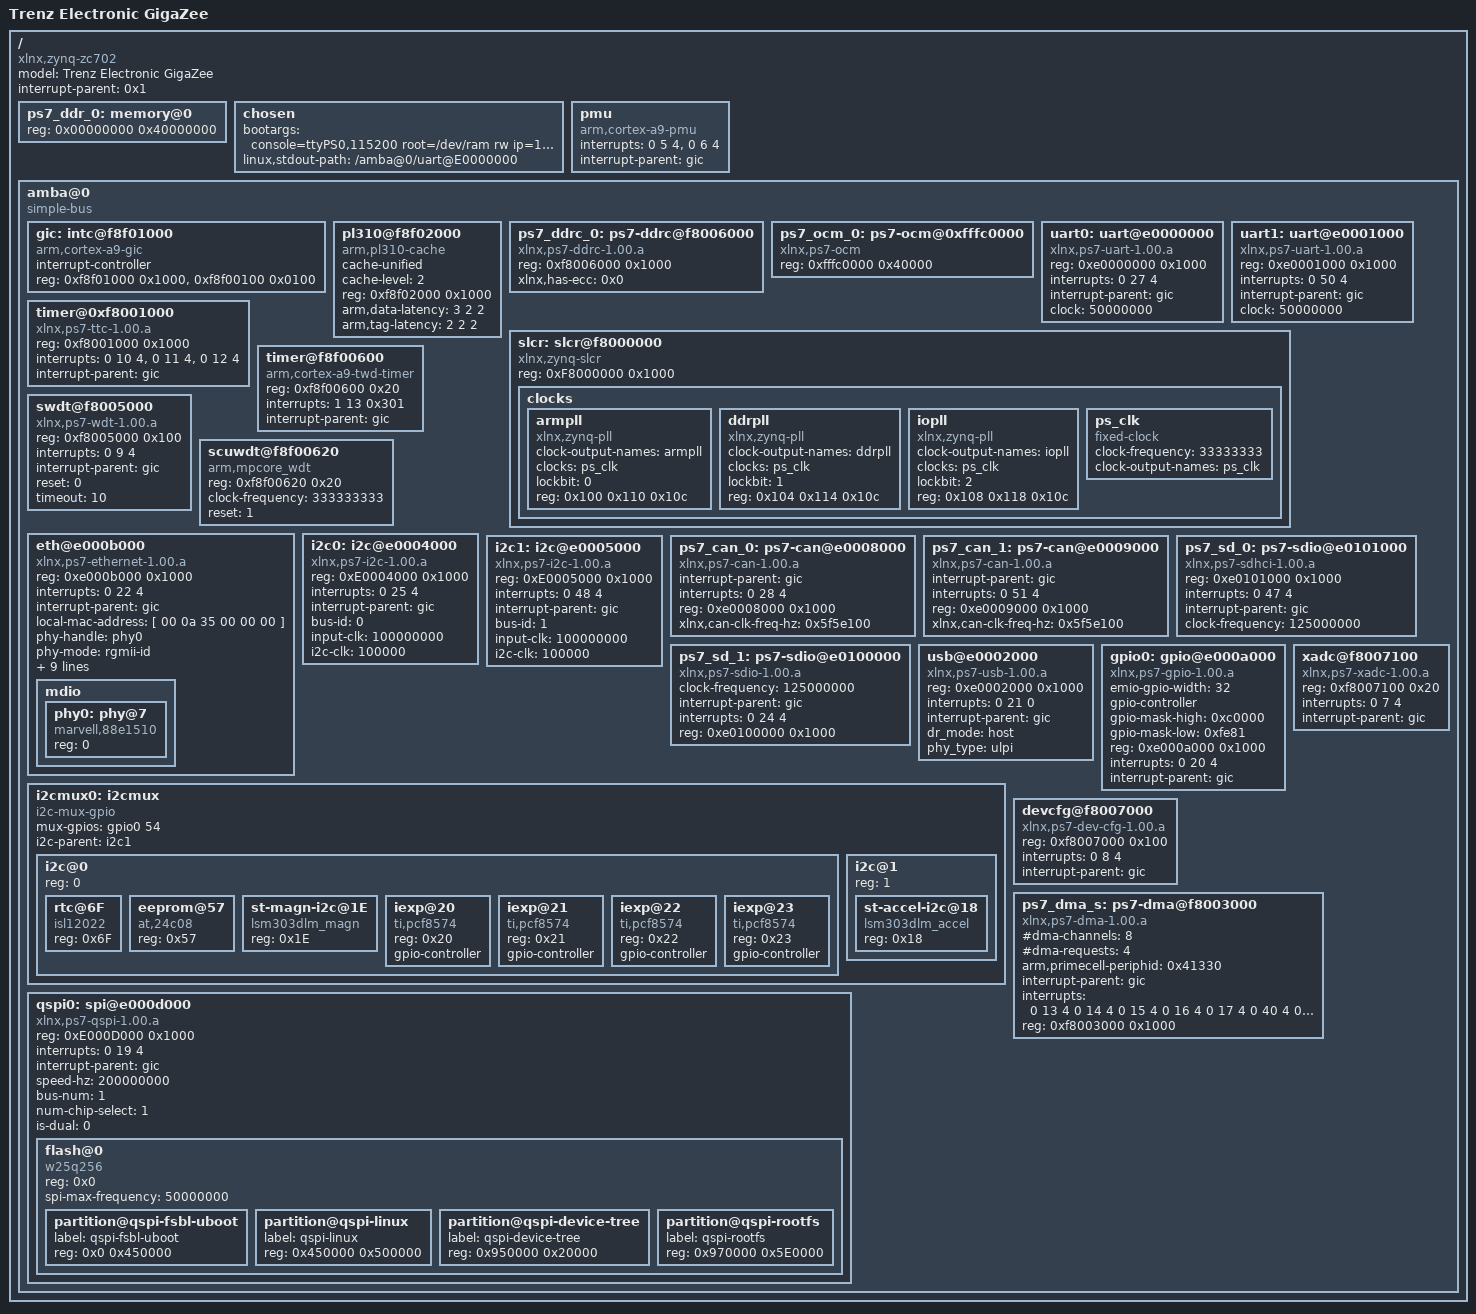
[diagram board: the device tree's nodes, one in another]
/*
-- Copyright (C) 2013 Trenz Electronic GmbH
--
-- Permission is hereby granted, free of charge, to any person obtaining a 
-- copy of this software and associated documentation files (the "Software"), 
-- to deal in the Software without restriction, including without limitation 
-- the rights to use, copy, modify, merge, publish, distribute, sublicense, 
-- and/or sell copies of the Software, and to permit persons to whom the 
-- Software is furnished to do so, subject to the following conditions:
-- 
-- The above copyright notice and this permission notice shall be included 
-- in all copies or substantial portions of the Software.
--
-- THE SOFTWARE IS PROVIDED "AS IS", WITHOUT WARRANTY OF ANY KIND, EXPRESS 
-- OR IMPLIED, INCLUDING BUT NOT LIMITED TO THE WARRANTIES OF MERCHANTABILITY, 
-- FITNESS FOR A PARTICULAR PURPOSE AND NONINFRINGEMENT. IN NO EVENT SHALL THE 
-- AUTHORS OR COPYRIGHT HOLDERS BE LIABLE FOR ANY CLAIM, DAMAGES OR OTHER 
-- LIABILITY, WHETHER IN AN ACTION OF CONTRACT, TORT OR OTHERWISE, ARISING 
-- FROM, OUT OF OR IN CONNECTION WITH THE SOFTWARE OR THE USE OR OTHER DEALINGS 
-- IN THE SOFTWARE.
 */
/dts-v1/;

/ {
	model = "Trenz Electronic GigaZee";
	compatible = "xlnx,zynq-zc702";
	#address-cells = <0x1>;
	#size-cells = <0x1>;
	interrupt-parent = <0x1>;

	ps7_ddr_0: memory@0 {
		device_type = "memory";
		reg = <0x00000000 0x40000000>;
	};

	chosen {
		/*bootargs = "console=ttyPS0,115200 root=/dev/ram rw ip=:::::eth0:dhcp earlyprintk";*/					/*rootfs in memory, DHCP */
		bootargs = "console=ttyPS0,115200 root=/dev/ram rw ip=192.168.42.50:::255.255.255.0::eth0 earlyprintk"; /*rootfs in memory, Static IP*/
		/*bootargs = "console=ttyPS0,115200 root=/dev/mmcblk0p1 rw rootwait ip=:::::eth0:dhcp earlyprintk";*/	/*rootfs at MMC */
		/*bootargs = "console=ttyPS0,115200 root=/dev/mmcblk1p2 rw rootwait ip=:::::eth0:dhcp earlyprintk";*/	/*rootfs at SD */
		linux,stdout-path = "/amba@0/uart@E0000000";	/*UART0 as console*/
	};

	pmu {
		compatible = "arm,cortex-a9-pmu";
		interrupts = <0 5 4>, <0 6 4>;
		interrupt-parent = <&gic>;
	};

	amba@0 {
		compatible = "simple-bus";
		#address-cells = <0x1>;
		#size-cells = <0x1>;
		ranges;

		gic: intc@f8f01000 {
			interrupt-controller;
			compatible = "arm,cortex-a9-gic";
			#interrupt-cells = <3>;
			reg = <0xf8f01000 0x1000>,
			      <0xf8f00100 0x0100>;
		};

		pl310@f8f02000 {
			compatible = "arm,pl310-cache";
			cache-unified;
			cache-level = <2>;
			reg = <0xf8f02000 0x1000>;
			arm,data-latency = <3 2 2>;
			arm,tag-latency = <2 2 2>;
		};

		ps7_ddrc_0: ps7-ddrc@f8006000 {
			compatible = "xlnx,ps7-ddrc-1.00.a", "xlnx,ps7-ddrc";
			reg = <0xf8006000 0x1000>;
			xlnx,has-ecc = <0x0>;
		} ;

		ps7_ocm_0: ps7-ocm@0xfffc0000 {
			compatible = "xlnx,ps7-ocm";
			reg = <0xfffc0000 0x40000>; /* 256k */
		};

		uart0: uart@e0000000 {
			compatible = "xlnx,ps7-uart-1.00.a";
			reg = <0xe0000000 0x1000>;
			interrupts = <0 27 4>;
			interrupt-parent = <&gic>;
			clock = <50000000>;
		};

        uart1: uart@e0001000 {
            compatible = "xlnx,ps7-uart-1.00.a";
            reg = <0xe0001000 0x1000>;
            interrupts = <0 50 4>;
            interrupt-parent = <&gic>;
            clock = <50000000>;
        };

		slcr: slcr@f8000000 {
			compatible = "xlnx,zynq-slcr";
			reg = <0xF8000000 0x1000>;
			clocks {
				#address-cells = <1>;
				#size-cells = <0>;
				armpll: armpll {
					#clock-cells = <0>;
					clock-output-names = "armpll";
					clocks = <&ps_clk>;
					compatible = "xlnx,zynq-pll";
					lockbit = <0>;
					reg = < 0x100 0x110 0x10c >;
				} ;
				ddrpll: ddrpll {
					#clock-cells = <0>;
					clock-output-names = "ddrpll";
					clocks = <&ps_clk>;
					compatible = "xlnx,zynq-pll";
					lockbit = <1>;
					reg = < 0x104 0x114 0x10c >;
				} ;
				iopll: iopll {
					#clock-cells = <0>;
					clock-output-names = "iopll";
					clocks = <&ps_clk>;
					compatible = "xlnx,zynq-pll";
					lockbit = <2>;
					reg = < 0x108 0x118 0x10c >;
				} ;
				ps_clk: ps_clk {
					#clock-cells = <0>;
					clock-frequency = <33333333>;
					clock-output-names = "ps_clk";
					compatible = "fixed-clock";
				} ;
			} ;
		};

		timer@0xf8001000 {
			compatible = "xlnx,ps7-ttc-1.00.a";
			reg = <0xf8001000 0x1000>;
			interrupts = <0 10 4>,<0 11 4>,<0 12 4>;
			interrupt-parent = <&gic>;
		};

		timer@f8f00600 {
			compatible = "arm,cortex-a9-twd-timer";
			reg = <0xf8f00600 0x20>;
			interrupts = <1 13 0x301>;
			interrupt-parent = <&gic>;
		};

		swdt@f8005000 {
			device_type = "watchdog";
			compatible = "xlnx,ps7-wdt-1.00.a";
			reg = <0xf8005000 0x100>;
			interrupts = <0 9 4>;
			interrupt-parent = <&gic>;
			reset = <0>;
			timeout = <10>;
		};

		scuwdt@f8f00620 {
			device_type = "watchdog";
			compatible = "arm,mpcore_wdt";
			reg = <0xf8f00620 0x20>;
			clock-frequency = <333333333>;
			reset = <1>;
		};

		eth@e000b000 {
			#address-cells = <0x1>;
			#size-cells = <0x0>;
			compatible = "xlnx,ps7-ethernet-1.00.a";
			reg = <0xe000b000 0x1000>;
			interrupts = <0 22 4>;
			interrupt-parent = <&gic>;
			local-mac-address = [ 00 0a 35 00 00 00 ];
			phy-handle = <&phy0>;
			phy-mode = "rgmii-id";
			xlnx,ptp-enet-clock = <111111111>;
			xlnx,slcr-div0-1000Mbps = <8>;
			xlnx,slcr-div0-100Mbps = <8>;
			xlnx,slcr-div0-10Mbps = <8>;
			xlnx,slcr-div1-1000Mbps = <1>;
			xlnx,slcr-div1-100Mbps = <5>;
			xlnx,slcr-div1-10Mbps = <50>;
			xlnx,eth-mode = <0x1>;
			xlnx,has-mdio = <0x1>;
			mdio {
				#address-cells = <1>;
				#size-cells = <0>;
				phy0: phy@7 {
					compatible = "marvell,88e1510";
					device_type = "ethernet-phy";
					reg = <0>;
				};
			};
		};

		i2c0: i2c@e0004000 {	/* I2C controller connected to MIO 10 11 */
			compatible = "xlnx,ps7-i2c-1.00.a";
			reg = <0xE0004000 0x1000>;
			interrupts = <0 25 4>;
			interrupt-parent = <&gic>;
			bus-id = <0>;
			input-clk = <100000000>;
			i2c-clk = <100000>;
		};

                i2c1: i2c@e0005000 {	/* I2C controller connected to CPLD - see i2cmux0 below*/
                        compatible = "xlnx,ps7-i2c-1.00.a";
                        reg = <0xE0005000 0x1000>;
                        interrupts = < 0 48 4 >;
                        interrupt-parent = <&gic>;
                        bus-id = <1>;
                        input-clk = <100000000>;
                        i2c-clk = <100000>;
                };


		ps7_can_0: ps7-can@e0008000 {
			compatible = "xlnx,ps7-can-1.00.a";
			interrupt-parent = <&gic>;
			interrupts = < 0 28 4 >;
			reg = < 0xe0008000 0x1000 >;
			xlnx,can-clk-freq-hz = <0x5f5e100>;
		};

		ps7_can_1: ps7-can@e0009000 {
			compatible = "xlnx,ps7-can-1.00.a";
			interrupt-parent = <&gic>;
			interrupts = < 0 51 4 >;
			reg = < 0xe0009000 0x1000 >;
			xlnx,can-clk-freq-hz = <0x5f5e100>;
		};

		ps7_sd_0: ps7-sdio@e0101000 {	/*SD1 MMC slot*/
			compatible = "xlnx,ps7-sdhci-1.00.a", "generic-sdhci";
			reg = <0xe0101000 0x1000>;
			interrupts = <0 47 4>;
			interrupt-parent = <&gic>;
			clock-frequency = <125000000>;
		};

                ps7_sd_1: ps7-sdio@e0100000 {	/*SD0 SD slot*/
                        clock-frequency = <125000000>;
                        compatible = "xlnx,ps7-sdio-1.00.a", "generic-sdhci";
                        interrupt-parent = <&gic>;
                        interrupts = < 0 24 4 >;
                        reg = < 0xe0100000 0x1000 >;
                } ;


		usb@e0002000 {
			compatible = "xlnx,ps7-usb-1.00.a";
			reg = <0xe0002000 0x1000>;
			interrupts = <0 21 0>;
			interrupt-parent = <&gic>;
			dr_mode = "host";
			phy_type = "ulpi";
		};

		gpio0: gpio@e000a000 {
			#gpio-cells = <2>;
			compatible = "xlnx,ps7-gpio-1.00.a";
			emio-gpio-width = <32>;
			gpio-controller ;
			gpio-mask-high = <0xc0000>;
			gpio-mask-low = <0xfe81>;
			reg = <0xe000a000 0x1000>;
			interrupts = <0 20 4>;
			interrupt-parent = <&gic>;
		};


		i2cmux0: i2cmux {	/* I2C mux in CPLD controlled by EMIO GPIO[0] (54)*/
			compatible = "i2c-mux-gpio";
			mux-gpios = <&gpio0 54 0>;
			i2c-parent = <&i2c1>;
			#address-cells = <1>;
			#size-cells = <0>;
			i2c@0 {		/* GPIO[54] = '0' */
				reg = <0>;
				#address-cells = <1>;
				#size-cells = <0>;
				rtc@6F {		/* Real Time Clock*/
					compatible = "isl12022";
					reg = <0x6F>;
				};

				/*There is no support of ISL12022 battery SRAM yet
				  this EEPROM driver possibly can handle single read/write transfers*/
				eeprom@57 {		/* Battry SRAM of RTC chip */
					compatible = "at,24c08";
					reg = <0x57>;
				};


				st-magn-i2c@1E {	/* Magnetometer */
					compatible = "lsm303dlm_magn";
					reg = <0x1E>;
				};
				
				iexp@20 {		/* GPIO in CPLD */
					#gpio-cells = <2>;
					compatible = "ti,pcf8574";
					reg = <0x20>;
					gpio-controller;
				};
				iexp@21 {		/* GPIO in CPLD */
					#gpio-cells = <2>;
					compatible = "ti,pcf8574";
					reg = <0x21>;
					gpio-controller;
				};
				iexp@22 {		/* GPIO in CPLD */
					#gpio-cells = <2>;
					compatible = "ti,pcf8574";
					reg = <0x22>;
					gpio-controller;
				};
				iexp@23 {		/* GPIO in CPLD */
					#gpio-cells = <2>;
					compatible = "ti,pcf8574";
					reg = <0x23>;
					gpio-controller;
				};
			};
			i2c@1 {		/* GPIO[54] = '1' */
				reg = <1>;
				#address-cells = <1>;
				#size-cells = <0>;
				st-accel-i2c@18 {	/* Accelerometer */
					compatible = "lsm303dlm_accel";
					reg = <0x18>;
				};
			};
		};

		qspi0: spi@e000d000 {	/* Onboard QSPI Flash */
			compatible = "xlnx,ps7-qspi-1.00.a";
			reg = <0xE000D000 0x1000>;
			interrupts = <0 19 4>;
			interrupt-parent = <&gic>;
			speed-hz = <200000000>;
			bus-num = <1>;
			num-chip-select = <1>;
			#address-cells = <1>;
			#size-cells = <0>;
			is-dual = <0>;
			flash@0 {
				compatible = "w25q256";
				reg = <0x0>;
				spi-max-frequency = <50000000>;
				#address-cells = <1>;
				#size-cells = <1>;
				partition@qspi-fsbl-uboot {
					label = "qspi-fsbl-uboot";
					reg = <0x0 0x450000>;
				};
				partition@qspi-linux {
					label = "qspi-linux";
					reg = <0x450000 0x500000>;
				};
				partition@qspi-device-tree {
					label = "qspi-device-tree";
					reg = <0x950000 0x20000>;
				};
				partition@qspi-rootfs {
					label = "qspi-rootfs";
					reg = <0x970000 0x5E0000>;
				};
			};
		};

		devcfg@f8007000 {
			compatible = "xlnx,ps7-dev-cfg-1.00.a";
			reg = <0xf8007000 0x100>;
			interrupts = <0 8 4>;
			interrupt-parent = <&gic>;
		};

		xadc@f8007100 {
			compatible = "xlnx,ps7-xadc-1.00.a";
			reg = <0xf8007100 0x20>;
			interrupts = <0 7 4>;
			interrupt-parent = <&gic>;
		};


		ps7_dma_s: ps7-dma@f8003000 {
			#dma-cells = <1>;
			#dma-channels = <8>;
			#dma-requests = <4>;
			arm,primecell-periphid = <0x41330>;
			compatible = "xlnx,ps7-dma-1.00.a", "arm,primecell", "arm,pl330";
			interrupt-parent = <&gic>;
			interrupts = < 0 13 4 0 14 4 0 15 4 0 16 4 0 17 4 0 40 4 0 41 4 0 42 4 0 43 4 >;
			reg = < 0xf8003000 0x1000 >;
		} ;
	};
};
